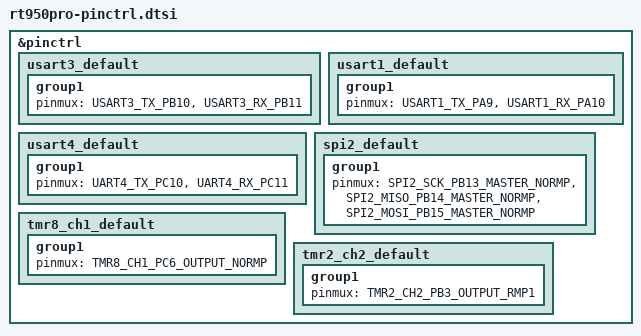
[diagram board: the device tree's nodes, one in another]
/*
 * SPDX-FileCopyrightText: Copyright 2020-2026 OpenRTX Contributors
 *
 * SPDX-License-Identifier: GPL-3.0-or-later
 */

#include <dt-bindings/pinctrl/at32f403av(g)xx-pinctrl.h>

&pinctrl {
	/* GPS module */
	usart3_default: usart3_default {
		group1 {
			pinmux = <USART3_TX_PB10>, <USART3_RX_PB11>;
		};
	};

	/* Bluetooth serial module */
	usart1_default: usart1_default {
		group1 {
			pinmux = <USART1_TX_PA9>, <USART1_RX_PA10>;
		};
	};

	/* UART4 on the programming cable connector */
	usart4_default: usart4_default {
		group1 {
			pinmux = <UART4_TX_PC10>, <UART4_RX_PC11>;
		};
	};

	/* External SPI NOR flash (factory data, calibration) */
	spi2_default: spi2_default {
		group1 {
			pinmux = <SPI2_SCK_PB13_MASTER_NORMP>,
				 <SPI2_MISO_PB14_MASTER_NORMP>,
				 <SPI2_MOSI_PB15_MASTER_NORMP>;
		};
	};

	/* LCD backlight PWM */
	tmr8_ch1_default: tmr8_ch1_default {
		group1 {
			pinmux = <TMR8_CH1_PC6_OUTPUT_NORMP>;
		};
	};

	/*
	 * Keypad backlight PWM. Remap 1 moves only TMR2's channel 1 and 2 pins;
	 * remap 3 would move channels 3 and 4 onto USART3's PB10 and PB11
	 */
	tmr2_ch2_default: tmr2_ch2_default {
		group1 {
			pinmux = <TMR2_CH2_PB3_OUTPUT_RMP1>;
		};
	};
};
